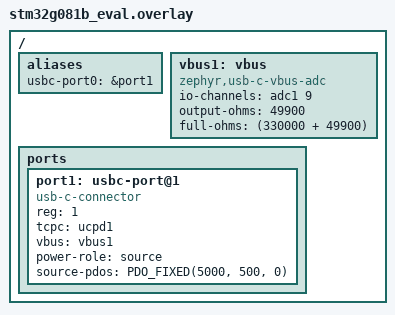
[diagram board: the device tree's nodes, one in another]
/*
 * Copyright (c) 2026 Alexander Wachter
 *
 * SPDX-License-Identifier: Apache-2.0
 */

#include <zephyr/dt-bindings/usb-c/pd.h>

/ {
	aliases {
		usbc-port0 = &port1;
	};

	vbus1: vbus {
		compatible = "zephyr,usb-c-vbus-adc";
		io-channels = <&adc1 9>;
		output-ohms = <49900>;
		full-ohms = <(330000 + 49900)>;
	};

	ports {
		#address-cells = <1>;
		#size-cells = <0>;

		port1: usbc-port@1 {
			compatible = "usb-c-connector";
			reg = <1>;
			tcpc = <&ucpd1>;
			vbus = <&vbus1>;
			power-role = "source";
			source-pdos = <PDO_FIXED(5000, 500, 0)>;
		};
	};
};
